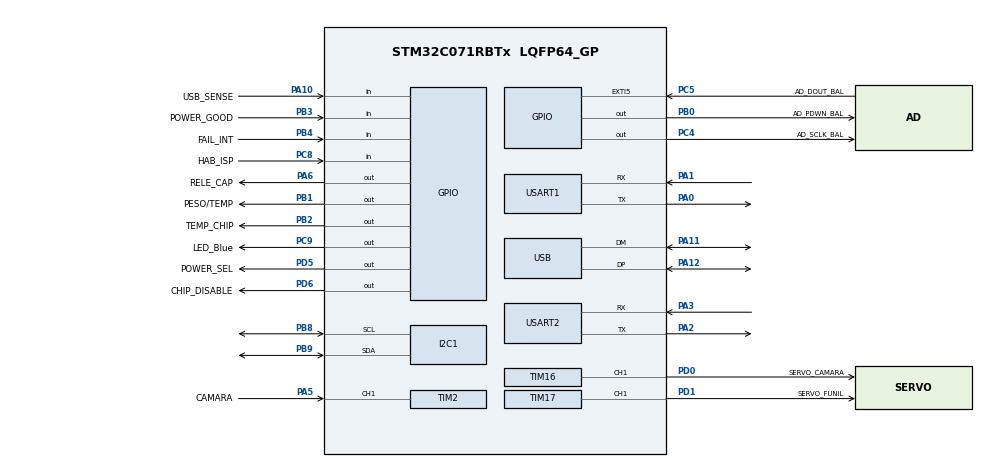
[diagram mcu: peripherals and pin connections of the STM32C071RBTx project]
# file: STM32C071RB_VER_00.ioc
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ADC1.ClockPrescaler=ADC_CLOCK_SYNC_PCLK_DIV4
ADC1.NbrOfConversionFlag=0
ADC1.SamplingTimeCommon1=ADC_SAMPLETIME_160CYCLES_5
ADC1.SelectedChannel=ADC_CHANNEL_TEMPSENSOR
ADC1.master=1
Dma.Request0=USART1_TX
Dma.Request1=USART1_RX
Dma.Request2=USART2_RX
Dma.Request3=USART2_TX
Dma.USART1_RX.1.Direction=DMA_PERIPH_TO_MEMORY
Dma.USART1_RX.1.EventEnable=DISABLE
Dma.USART1_RX.1.Instance=DMA1_Channel2
Dma.USART1_RX.1.MemDataAlignment=DMA_MDATAALIGN_BYTE
Dma.USART1_RX.1.MemInc=DMA_MINC_ENABLE
Dma.USART1_RX.1.Mode=DMA_NORMAL
Dma.USART1_RX.1.PeriphDataAlignment=DMA_PDATAALIGN_BYTE
Dma.USART1_RX.1.PeriphInc=DMA_PINC_DISABLE
Dma.USART1_RX.1.Polarity=HAL_DMAMUX_REQ_GEN_RISING
Dma.USART1_RX.1.Priority=DMA_PRIORITY_LOW
Dma.USART1_RX.1.RequestNumber=1
Dma.USART1_RX.1.SignalID=NONE
Dma.USART1_RX.1.SyncEnable=DISABLE
Dma.USART1_RX.1.SyncPolarity=HAL_DMAMUX_SYNC_NO_EVENT
Dma.USART1_RX.1.SyncRequestNumber=1
Dma.USART1_RX.1.SyncSignalID=NONE
Dma.USART1_TX.0.Direction=DMA_MEMORY_TO_PERIPH
Dma.USART1_TX.0.EventEnable=DISABLE
Dma.USART1_TX.0.Instance=DMA1_Channel1
Dma.USART1_TX.0.MemDataAlignment=DMA_MDATAALIGN_BYTE
Dma.USART1_TX.0.MemInc=DMA_MINC_ENABLE
Dma.USART1_TX.0.Mode=DMA_NORMAL
Dma.USART1_TX.0.PeriphDataAlignment=DMA_PDATAALIGN_BYTE
Dma.USART1_TX.0.PeriphInc=DMA_PINC_DISABLE
Dma.USART1_TX.0.Polarity=HAL_DMAMUX_REQ_GEN_RISING
Dma.USART1_TX.0.Priority=DMA_PRIORITY_LOW
Dma.USART1_TX.0.RequestNumber=1
Dma.USART1_TX.0.SignalID=NONE
Dma.USART1_TX.0.SyncEnable=DISABLE
Dma.USART1_TX.0.SyncPolarity=HAL_DMAMUX_SYNC_NO_EVENT
Dma.USART1_TX.0.SyncRequestNumber=1
Dma.USART1_TX.0.SyncSignalID=NONE
Dma.USART2_RX.2.Direction=DMA_PERIPH_TO_MEMORY
Dma.USART2_RX.2.EventEnable=DISABLE
Dma.USART2_RX.2.Instance=DMA1_Channel3
Dma.USART2_RX.2.MemDataAlignment=DMA_MDATAALIGN_BYTE
Dma.USART2_RX.2.MemInc=DMA_MINC_ENABLE
Dma.USART2_RX.2.Mode=DMA_NORMAL
Dma.USART2_RX.2.PeriphDataAlignment=DMA_PDATAALIGN_BYTE
Dma.USART2_RX.2.PeriphInc=DMA_PINC_DISABLE
Dma.USART2_RX.2.Polarity=HAL_DMAMUX_REQ_GEN_RISING
Dma.USART2_RX.2.Priority=DMA_PRIORITY_LOW
Dma.USART2_RX.2.RequestNumber=1
Dma.USART2_RX.2.SignalID=NONE
Dma.USART2_RX.2.SyncEnable=DISABLE
Dma.USART2_RX.2.SyncPolarity=HAL_DMAMUX_SYNC_NO_EVENT
Dma.USART2_RX.2.SyncRequestNumber=1
Dma.USART2_RX.2.SyncSignalID=NONE
Dma.USART2_TX.3.Direction=DMA_MEMORY_TO_PERIPH
Dma.USART2_TX.3.EventEnable=DISABLE
Dma.USART2_TX.3.Instance=DMA1_Channel4
Dma.USART2_TX.3.MemDataAlignment=DMA_MDATAALIGN_BYTE
Dma.USART2_TX.3.MemInc=DMA_MINC_ENABLE
Dma.USART2_TX.3.Mode=DMA_NORMAL
Dma.USART2_TX.3.PeriphDataAlignment=DMA_PDATAALIGN_BYTE
Dma.USART2_TX.3.PeriphInc=DMA_PINC_DISABLE
Dma.USART2_TX.3.Polarity=HAL_DMAMUX_REQ_GEN_RISING
Dma.USART2_TX.3.Priority=DMA_PRIORITY_LOW
Dma.USART2_TX.3.RequestNumber=1
Dma.USART2_TX.3.SignalID=NONE
Dma.USART2_TX.3.SyncEnable=DISABLE
Dma.USART2_TX.3.SyncPolarity=HAL_DMAMUX_SYNC_NO_EVENT
Dma.USART2_TX.3.SyncRequestNumber=1
Dma.USART2_TX.3.SyncSignalID=NONE
I2C1.Timing=0x10805D88
Mcu.Family=STM32C0
Mcu.Name=STM32C071RBTx
Mcu.Package=LQFP64_GP
NVIC.DMA1_Channel1_IRQn=true\:3\:0\:true\:false\:true\:false\:true\:true
NVIC.DMA1_Channel2_3_IRQn=true\:3\:0\:true\:false\:true\:false\:true\:true
NVIC.DMAMUX1_DMA1_CH4_5_IRQn=true\:3\:0\:true\:false\:true\:false\:true\:true
NVIC.EXTI4_15_IRQn=true\:3\:0\:true\:false\:true\:true\:true\:true
NVIC.TIM14_IRQn=true\:3\:0\:true\:false\:true\:true\:true\:true
NVIC.USART1_IRQn=true\:3\:0\:true\:false\:true\:true\:true\:true
NVIC.USART2_IRQn=true\:3\:0\:true\:false\:true\:true\:true\:true
PA0.Mode=Asynchronous
PA0.Signal=USART1_TX
PA1.Mode=Asynchronous
PA1.Signal=USART1_RX
PA10.GPIO_Label=USB_SENSE
PA10.Signal=GPIO_Input
PA11\ [PA9].Mode=Device
PA11\ [PA9].Signal=USB_DM
PA12\ [PA10].Mode=Device
PA12\ [PA10].Signal=USB_DP
PA13.Mode=Serial_Wire
PA13.Signal=DEBUG_SWDIO
PA14-BOOT0.Mode=Serial_Wire
PA14-BOOT0.Signal=DEBUG_SWCLK
PA2.Mode=Asynchronous
PA2.Signal=USART2_TX
PA3.Mode=Asynchronous
PA3.Signal=USART2_RX
PA5.GPIO_Label=CAMARA
PA5.Signal=S_TIM2_CH1
PA6.GPIO_Label=RELE_CAP
PA6.Signal=GPIO_Output
PB0.GPIO_Label=AD_PDWN_BAL
PB0.Signal=GPIO_Output
PB1.GPIO_Label=PESO/TEMP
PB1.Signal=GPIO_Output
PB2.GPIO_Label=TEMP_CHIP
PB2.Signal=GPIO_Output
PB3.GPIO_Label=POWER_GOOD
PB3.Signal=GPIO_Input
PB4.GPIO_Label=FAIL_INT
PB4.Signal=GPIO_Input
PB8.Mode=I2C
PB8.Signal=I2C1_SCL
PB9.Mode=I2C
PB9.Signal=I2C1_SDA
PC14-OSCX_IN(PC14).Mode=LSE-External-Oscillator
PC14-OSCX_IN(PC14).Signal=RCC_OSCX_IN
PC15-OSCX_OUT(PC15).Mode=LSE-External-Oscillator
PC15-OSCX_OUT(PC15).Signal=RCC_OSCX_OUT
PC4.GPIO_Label=AD_SCLK_BAL
PC4.Signal=GPIO_Output
PC5.GPIO_Label=AD_DOUT_BAL
PC5.GPIO_ModeDefaultEXTI=GPIO_MODE_IT_FALLING
PC5.Signal=GPXTI5
PC8.GPIO_Label=HAB_ISP
PC8.Signal=GPIO_Input
PC9.GPIO_Label=LED_Blue
PC9.Signal=GPIO_Output
PD0.GPIO_Label=SERVO_CAMARA
PD0.Signal=S_TIM16_CH1
PD1.GPIO_Label=SERVO_FUNIL
PD1.Signal=S_TIM17_CH1
PD5.GPIO_Label=POWER_SEL
PD5.Signal=GPIO_Output
PD6.GPIO_Label=CHIP_DISABLE
PD6.Signal=GPIO_Output
PF0-OSC_IN(PF0).Mode=HSE-External-Oscillator
PF0-OSC_IN(PF0).Signal=RCC_OSC_IN
PF1-OSC_OUT(PF1).Mode=HSE-External-Oscillator
PF1-OSC_OUT(PF1).Signal=RCC_OSC_OUT
ProjectManager.HeapSize=0x200
ProjectManager.StackSize=0x400
ProjectManager.TargetToolchain=MDK-ARM V5.39
RCC.ADCFreq_Value=48000000
RCC.AHBFreq_Value=48000000
RCC.CortexFreq_Value=48000000
RCC.EXTERNAL_CLOCK_VALUE=12288000
RCC.HCLKFreq_Value=48000000
RCC.HSE_VALUE=12000000
RCC.HSI48_VALUE=48000000
RCC.HSI_VALUE=48000000
RCC.RTCClockSelection=RCC_RTCCLKSOURCE_LSE
RCC.SYSCLKFreq_VALUE=48000000
RCC.SYSCLKSource=RCC_SYSCLKSOURCE_HSIUSB48
RTC.Format=RTC_FORMAT_BIN
SH.S_TIM16_CH1.0=TIM16_CH1,PWM Generation1 CH1
SH.S_TIM17_CH1.0=TIM17_CH1,PWM Generation1 CH1
SH.S_TIM2_CH1.0=TIM2_CH1,TriggerSource_TI1FP1
TIM14.Period=999
TIM14.Prescaler=47
TIM16.Channel=TIM_CHANNEL_1
TIM17.Channel=TIM_CHANNEL_1
USART1.VirtualMode-Asynchronous=VM_ASYNC
USART2.VirtualMode-Asynchronous=VM_ASYNC
USB.VirtualMode=Device_Only
USB.battery_charging_enable=DISABLE
VP_ADC1_TempSens_Input.Mode=IN-TempSens
VP_CRC_VS_CRC.Mode=CRC_Activate
VP_RTC_VS_RTC_Activate.Mode=RTC_Enabled
VP_RTC_VS_RTC_Calendar.Mode=RTC_Calendar
VP_TIM14_VS_ClockSourceINT.Mode=Enable_Timer
VP_TIM16_VS_ClockSourceINT.Mode=Enable_Timer
VP_TIM17_VS_ClockSourceINT.Mode=Enable_Timer
VP_TIM2_VS_ControllerModeClock.Mode=Clock Mode
board=custom

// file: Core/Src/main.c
/* USER CODE BEGIN Header */
/**
  ******************************************************************************
  * @file           : main.c
  * @brief          : Main program body
  ******************************************************************************
  * @attention
  *
  * Copyright (c) 2025 STMicroelectronics.
  * All rights reserved.
  *
  * This software is licensed under terms that can be found in the LICENSE file
  * in the root directory of this software component.
  * If no LICENSE file comes with this software, it is provided AS-IS.
  *
  ******************************************************************************
  */
/* USER CODE END Header */
#include "main.h"
#include "adc.h"
#include "crc.h"
#include "dma.h"
#include "i2c.h"
#include "rtc.h"
#include "tim.h"
#include "usart.h"
#include "usb.h"
#include "gpio.h"
#include "app_manager.h"
#include "retarget.h"

void SystemClock_Config(void);

int main(void)
{

  /* MCU Configuration--------------------------------------------------------*/

  /* Reset of all peripherals, Initializes the Flash interface and the Systick. */
  HAL_Init();

  /* Configure the system clock */
  SystemClock_Config();

  /* Initialize all configured peripherals */
  MX_GPIO_Init();
  MX_DMA_Init();
  MX_ADC1_Init();
  MX_CRC_Init();
  MX_I2C1_Init();
  MX_RTC_Init();
  MX_TIM16_Init();
  MX_TIM17_Init();
  MX_USART1_UART_Init();
  MX_USART2_UART_Init();
  MX_USB_PCD_Init();
  MX_TIM2_Init();
  MX_TIM14_Init();
  /* USER CODE BEGIN 2 */
	Retarget_Init(&huart1, &huart2);

	App_Manager_Init();

	if (!App_Manager_Run_Self_Diagnostics(PRINCIPAL))
  {
      printf("ERRO FATAL DURANTE O AUTODIAGNOSTICO!\r\n");
      while(1) {}
  }
	HAL_TIM_Base_Start_IT(&htim14);
  /* USER CODE END 2 */

  /* Infinite loop */
  while (1)
  {
		App_Manager_Process();
  }
}

void SystemClock_Config(void)
{
  RCC_OscInitTypeDef RCC_OscInitStruct = {0};
  RCC_ClkInitTypeDef RCC_ClkInitStruct = {0};

  __HAL_FLASH_SET_LATENCY(FLASH_LATENCY_1);

  /** Configure LSE Drive Capability
  */
  __HAL_RCC_LSEDRIVE_CONFIG(RCC_LSEDRIVE_LOW);

  /** Initializes the RCC Oscillators according to the specified parameters
  * in the RCC_OscInitTypeDef structure.
  */
  RCC_OscInitStruct.OscillatorType = RCC_OSCILLATORTYPE_LSE|RCC_OSCILLATORTYPE_HSI48;
  RCC_OscInitStruct.LSEState = RCC_LSE_ON;
  RCC_OscInitStruct.HSI48State = RCC_HSI48_ON;

  if (HAL_RCC_OscConfig(&RCC_OscInitStruct) != HAL_OK)
  {
    Error_Handler();
  }

  /** Initializes the CPU, AHB and APB buses clocks
  */
  RCC_ClkInitStruct.ClockType = RCC_CLOCKTYPE_HCLK|RCC_CLOCKTYPE_SYSCLK
                              |RCC_CLOCKTYPE_PCLK1;
  RCC_ClkInitStruct.SYSCLKSource = RCC_SYSCLKSOURCE_HSIUSB48;
  RCC_ClkInitStruct.SYSCLKDivider = RCC_SYSCLK_DIV1;
  RCC_ClkInitStruct.AHBCLKDivider = RCC_HCLK_DIV1;
  RCC_ClkInitStruct.APB1CLKDivider = RCC_APB1_DIV1;

  if (HAL_RCC_ClockConfig(&RCC_ClkInitStruct, FLASH_LATENCY_1) != HAL_OK)
  {
    Error_Handler();
  }
}

void Error_Handler(void)
{
  __disable_irq();
  while (1)
  {
  }
}
